# S32R372 register map
Vendor: Freescale Semiconductor, Inc.; Series: Qorivva; File version: 1.6
Registers are 32-bit, read-write, reset 0x0 unless marked. A register's access mark holds for its fields unless they carry their own. Offsets are from the block's base; [hi:lo] are bit positions; 'fields as' and 'values as' point back to an identical list.

## PCM — Platform Configuration Module
Base 0xFC028000; register names take the prefix PCM_
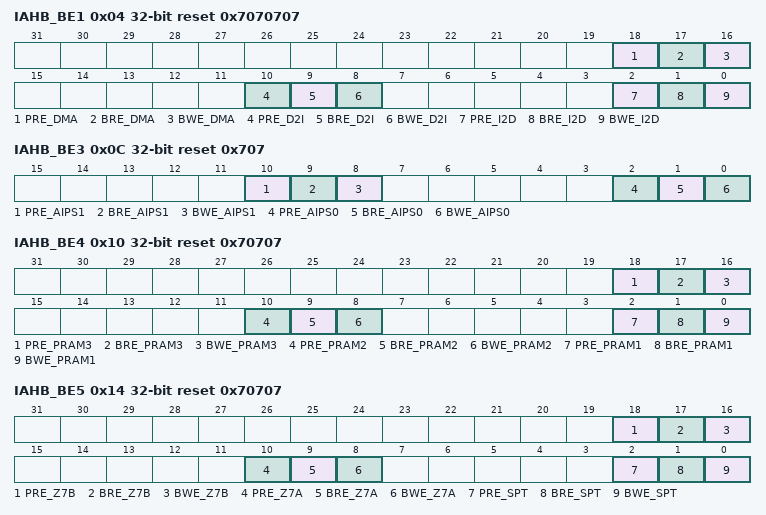
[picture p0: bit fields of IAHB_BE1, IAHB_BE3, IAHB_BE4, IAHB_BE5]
0x04 IAHB_BE1 reset 0x7070707 — IAHB Burst Enable 1 Register
  [18] PRE_DMA — Pending read enable (PRE) DMA This bit controls the pending read transactions for the bus gasket for a concentrator that includes the DMA
    0=Pending reads are disabled; 1=Pending reads are enabled
  [17] BRE_DMA — Burst read enable (BRE) DMA This bit controls the burst read transactions for the bus gasket for a concentrator that includes the DMA
    0=Burst reads are converted into a series of single transactions on the slave side of the gasket; 1=Burst reads are optimized for best system performance
  [16] BWE_DMA — Burst write enable (BWE) DMA This bit controls the burst write transactions for the bus gasket for a concentrator that includes the DMA
    0=Burst writes are converted into a series of single transactions on the slave side of the gasket; 1=Burst writes are optimized for best system performance. Note this setting treats writes as "imprecise" such that an error response on any beat of the burst is reported on the last beat.
  [10] PRE_D2I — Pending read enable (PRE) D2I This bit controls the pending read transactions for the bus gasket for transactions going from the Data crossbar to the Instruction Crossbar
    0=Pending reads are disabled; 1=Pending writes are enabled
  [9] BRE_D2I — Burst read enable (BRE) D2I This bit controls the burst read transactions for the bus gasket for transactions going from the Data crossbar to the Instruction Crossbar
    values as BRE_DMA
  [8] BWE_D2I — Burst write enable (BWE) D2I This bit controls the burst write transactions for the bus gasket for transactions going from the Data crossbar to the Instruction Crossbar
    values as BWE_DMA
  [2] PRE_I2D — Pending read enable (PRE) I2D This bit controls the pending read transactions for the bus gasket for transactions going from the Instruction crossbar to the Data Crossbar
    0=Pending reads are disabled; 1=Pending reads are enabled
  [1] BRE_I2D — Burst read enable (BRE) I2D This bit controls the burst read transactions for the bus gasket for transactions going from the Instruction crossbar to the Data Crossbar
    values as BRE_DMA
  [0] BWE_I2D — Burst write enable (BWE) I2D This bit controls the burst write transactions for the bus gasket for transactions going from the Instruction crossbar to the Data Crossbar
    values as BWE_DMA
0x0C IAHB_BE3 reset 0x707 — IAHB Burst Enable 3 Register
  [10] PRE_AIPS1 — Pending read enable (PRE) AIPS1 This bit controls the pending read transactions for the bus gasket between the Data crossbar and the AIPS1
    0=Pending reads are disabled; 1=Pending writes are enabled
  [9] BRE_AIPS1 — Burst read enable (BRE) AIPS1 This bit controls the burst read transactions for the bus gasket between the Data crossbar and the AIPS1
    values as IAHB_BE1.BRE_DMA
  [8] BWE_AIPS1 — Burst write enable (BWE) AIPS1 This bit controls the burst write transactions for the bus gasket between the Data crossbar and the AIPS1
    values as IAHB_BE1.BWE_DMA
  [2] PRE_AIPS0 — Pending read enable (PRE) AIPS0 This bit controls the pending read transactions for the bus gasket between the Data crossbar and the AIPS0
    0=Pending reads are disabled; 1=Pending reads are enabled
  [1] BRE_AIPS0 — Burst read enable (BRE) AIPS0 This bit controls the burst read transactions for the bus gasket between the Data crossbar and the AIPS0
    values as IAHB_BE1.BRE_DMA
  [0] BWE_AIPS0 — Burst write enable (BWE) AIPS0 This bit controls the burst write transactions for the bus gasket between the Data crossbar and the AIPS0
    values as IAHB_BE1.BWE_DMA
0x10 IAHB_BE4 reset 0x70707 — IAHB Burst Enable 4 Register
  [18] PRE_PRAM3 — Pending read enable (PRE) PRAM2 This bit controls the pending read transactions for the bus gasket between the Data crossbar and the pram_port2
    0=Pending reads are disabled; 1=Pending reads are enabled
  [17] BRE_PRAM3 — Burst read enable (BRE) PRAM2 This bit controls the burst read transactions for the bus gasket between the Data crossbar and the pram_port2
    values as IAHB_BE1.BRE_DMA
  [16] BWE_PRAM3 — Burst write enable (BWE) PRAM2 This bit controls the burst write transactions for the bus gasket between the Data crossbar and the pram_port2
    values as IAHB_BE1.BWE_DMA
  [10] PRE_PRAM2 — Pending read enable (PRE) PRAM1 This bit controls the pending read transactions for the bus gasket between the Data crossbar and the pram_port1
    0=Pending reads are disabled; 1=Pending writes are enabled
  [9] BRE_PRAM2 — Burst read enable (BRE) PRAM1 This bit controls the burst read transactions for the bus gasket between the Data crossbar and the pram_port1
    values as IAHB_BE1.BRE_DMA
  [8] BWE_PRAM2 — Burst write enable (BWE) PRAM1 This bit controls the burst write transactions for the bus gasket between the Data crossbar and the pram_port1
    values as IAHB_BE1.BWE_DMA
  [2] PRE_PRAM1 — Pending read enable (PRE) PRAM0 This bit controls the pending read transactions for the bus gasket between the Data crossbar and the pram_port0
    0=Pending reads are disabled; 1=Pending reads are enabled
  [1] BRE_PRAM1 — Burst read enable (BRE) PRAM0 This bit controls the burst read transactions for the bus gasket between the Data crossbar and the pram_port0
    values as IAHB_BE1.BRE_DMA
  [0] BWE_PRAM1 — Burst write enable (BWE) PRAM0 This bit controls the burst write transactions for the bus gasket between the Data crossbar and the pram_port0
    values as IAHB_BE1.BWE_DMA
0x14 IAHB_BE5 reset 0x70707 — IAHB Burst Enable 5 Register
  [18] PRE_Z7B — Pending read enable (PRE) Z7B This bit controls the pending read transactions for the bus gasket between the Data crossbar and the z7b TCM interface
    0=Pending reads are disabled; 1=Pending reads are enabled
  [17] BRE_Z7B — Burst read enable (BRE) Z7B This bit controls the burst read transactions for the bus gasket between the Data crossbar and the z7b TCM interface
    values as IAHB_BE1.BRE_DMA
  [16] BWE_Z7B — Burst write enable (BWE) Z7B This bit controls the burst write transactions for the bus gasket between the Data crossbar and the z7b TCM interface
    values as IAHB_BE1.BWE_DMA
  [10] PRE_Z7A — Pending read enable (PRE) Z7A This bit controls the pending read transactions for the bus gasket between the Data crossbar and the z7a TCM interface
    0=Pending reads are disabled; 1=Pending writes are enabled
  [9] BRE_Z7A — Burst read enable (BRE) Z7A This bit controls the burst read transactions for the bus gasket between the Data crossbar and the z7a TCM interface
    values as IAHB_BE1.BRE_DMA
  [8] BWE_Z7A — Burst write enable (BWE) Z7A This bit controls the burst write transactions for the bus gasket between the Data crossbar and the z7a TCM interface
    values as IAHB_BE1.BWE_DMA
  [2] PRE_SPT — Pending read enable (PRE) SPT This bit controls the pending read transactions for the bus gasket between the SPT and the Data crossbar
    0=Pending reads are disabled; 1=Pending reads are enabled
  [1] BRE_SPT — Burst read enable (BRE) SPT This bit controls the burst read transactions for the bus gasket between the SPT and the Data crossbar
    values as IAHB_BE1.BRE_DMA
  [0] BWE_SPT — Burst write enable (BWE) SPT This bit controls the burst write transactions for the bus gasket between the SPT and the Data crossbar
    values as IAHB_BE1.BWE_DMA
